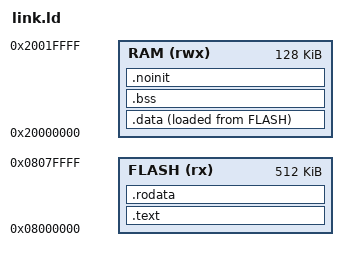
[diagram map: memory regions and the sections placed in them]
MEMORY
{
  FLASH (rx)  : ORIGIN = 0x08000000, LENGTH = 512K
  RAM   (rwx) : ORIGIN = 0x20000000, LENGTH = 128K
}
ENTRY(Reset_Handler)
SECTIONS
{
  .text : { KEEP(*(.isr_vector)) *(.text*) } > FLASH
  .rodata : { *(.rodata*) } > FLASH
  _sidata = LOADADDR(.data);
  .data : { _sdata = .; *(.data*) _edata = .; } > RAM AT > FLASH
  .bss (NOLOAD) : { _sbss = .; *(.bss*) *(COMMON) _ebss = .; } > RAM
  .noinit (NOLOAD) : { *(.noinit*) } > RAM
  /DISCARD/ : { *(.ARM.exidx*) *(.comment) }
}
